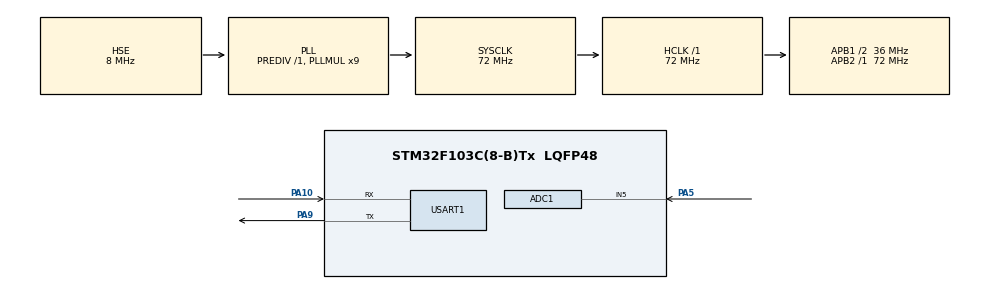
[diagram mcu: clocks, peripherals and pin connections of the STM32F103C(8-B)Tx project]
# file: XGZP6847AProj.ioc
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ADC1.Channel-0\#ChannelRegularConversion=ADC_CHANNEL_5
ADC1.ContinuousConvMode=ENABLE
ADC1.NbrOfConversionFlag=1
ADC1.Rank-0\#ChannelRegularConversion=1
ADC1.SamplingTime-0\#ChannelRegularConversion=ADC_SAMPLETIME_1CYCLE_5
ADC1.master=1
Mcu.Family=STM32F1
Mcu.Name=STM32F103C(8-B)Tx
Mcu.Package=LQFP48
NVIC.PriorityGroup=NVIC_PRIORITYGROUP_4
NVIC.USART1_IRQn=true\:0\:0\:false\:false\:true\:true\:true\:true
PA10.Mode=Asynchronous
PA10.Signal=USART1_RX
PA13.Mode=Serial_Wire
PA13.Signal=SYS_JTMS-SWDIO
PA14.Mode=Serial_Wire
PA14.Signal=SYS_JTCK-SWCLK
PA5.Signal=ADCx_IN5
PA9.Mode=Asynchronous
PA9.Signal=USART1_TX
PD0-OSC_IN.Mode=HSE-External-Oscillator
PD0-OSC_IN.Signal=RCC_OSC_IN
PD1-OSC_OUT.Mode=HSE-External-Oscillator
PD1-OSC_OUT.Signal=RCC_OSC_OUT
ProjectManager.HeapSize=0x200
ProjectManager.StackSize=0x400
ProjectManager.TargetToolchain=MDK-ARM V5.32
RCC.ADCPresc=RCC_ADCPCLK2_DIV6
RCC.AHBFreq_Value=72000000
RCC.APB1CLKDivider=RCC_HCLK_DIV2
RCC.APB1Freq_Value=36000000
RCC.APB1TimFreq_Value=72000000
RCC.APB2Freq_Value=72000000
RCC.APB2TimFreq_Value=72000000
RCC.HCLKFreq_Value=72000000
RCC.PLLMUL=RCC_PLL_MUL9
RCC.PLLSourceVirtual=RCC_PLLSOURCE_HSE
RCC.SYSCLKFreq_VALUE=72000000
RCC.SYSCLKSource=RCC_SYSCLKSOURCE_PLLCLK
RCC.USBFreq_Value=72000000
SH.ADCx_IN5.0=ADC1_IN5,IN5
USART1.VirtualMode=VM_ASYNC
board=custom

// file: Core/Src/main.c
/* USER CODE BEGIN Header */
/**
 ******************************************************************************
 * @file           : main.c
 * @brief          : Main program body
 ******************************************************************************
 * @attention
 *
 * Copyright (c) 2024 STMicroelectronics.
 * All rights reserved.
 *
 * This software is licensed under terms that can be found in the LICENSE file
 * in the root directory of this software component.
 * If no LICENSE file comes with this software, it is provided AS-IS.
 *
 ******************************************************************************
 */
/* USER CODE END Header */
#include "main.h"
#include "adc.h"
#include "gpio.h"
#include "usart.h"

/* USER CODE BEGIN Includes */
#include "Serial.h"
/* USER CODE END Includes */

/* USER CODE BEGIN PD */
#define RX_BUFFER_SIZE 5 // 定义接收缓冲区大小
/* USER CODE END PD */

/* USER CODE BEGIN PV */
int16_t ADC_Value;
float Pressure_V;
float pressure;

uint8_t RxBuffer[RX_BUFFER_SIZE]; // 接收缓冲区

int16_t RxNUM = 0;
/* USER CODE END PV */

void SystemClock_Config(void);

/* USER CODE BEGIN 0 */
HAL_StatusTypeDef HalState;
uint16_t Ret;
uint16_t Start_GetResult(void)
{
    Ret = HAL_ADC_GetValue(&hadc1);
    return Ret;
}

float map(float x, float in_min, float in_max, float out_min, float out_max)
{
    return (x - in_min) * (out_max - out_min) / (in_max - in_min) + out_min;
}

// usart1中断函数
void HAL_UART_RxCpltCallback(UART_HandleTypeDef* huart)
{
    if (huart == &huart1) {
        if (ByteRecv == 'a') {
            Serial_printf("ADC_Value:%f\n", ADC_Value);
            HAL_UART_Receive_IT(&huart1, &ByteRecv, 1);
        } else if (ByteRecv == 's') {
            Serial_printf("ADC_Value:%f\n", ADC_Value);
            HAL_UART_Receive_IT(&huart1, &ByteRecv, 1);
        }
    }
}

/* USER CODE END 0 */

int main(void)
{

    /* MCU Configuration--------------------------------------------------------*/

    /* Reset of all peripherals, Initializes the Flash interface and the Systick. */
    HAL_Init();

    /* Configure the system clock */
    SystemClock_Config();

    /* Initialize all configured peripherals */
    MX_GPIO_Init();
    MX_ADC1_Init();
    MX_USART1_UART_Init();
    /* USER CODE BEGIN 2 */

    HAL_ADCEx_Calibration_Start(&hadc1); // ADC校准

    HAL_ADC_Start(&hadc1); // 启动ADC转换  (!!!!continuous conversion mode)

    HAL_UART_Receive_IT(&huart1, &ByteRecv, 1); // start itrpt receive a byte
    /* USER CODE END 2 */

    /* Infinite loop */
    /* USER CODE BEGIN WHILE */
    while (1) {
        ADC_Value = Start_GetResult();
        Pressure_V = (float)(ADC_Value * 3.3) / 4096.0; //(ADC_Value/4096.0) * 3.3

        // 0-40kPa 0-3.3V   (pa)
        pressure = map(Pressure_V, 0.0, 3.3, 0.0, 40000.0);
        Serial_printf("pressure,Pressure_V,ADC_Value:%f,%f,%d\n", pressure, Pressure_V, ADC_Value);

        HAL_Delay(100);
        /* USER CODE END WHILE */

    }
}

void SystemClock_Config(void)
{
    RCC_OscInitTypeDef RCC_OscInitStruct = { 0 };
    RCC_ClkInitTypeDef RCC_ClkInitStruct = { 0 };
    RCC_PeriphCLKInitTypeDef PeriphClkInit = { 0 };

    /** Initializes the RCC Oscillators according to the specified parameters
     * in the RCC_OscInitTypeDef structure.
     */
    RCC_OscInitStruct.OscillatorType = RCC_OSCILLATORTYPE_HSE;
    RCC_OscInitStruct.HSEState = RCC_HSE_ON;
    RCC_OscInitStruct.HSEPredivValue = RCC_HSE_PREDIV_DIV1;
    RCC_OscInitStruct.HSIState = RCC_HSI_ON;
    RCC_OscInitStruct.PLL.PLLState = RCC_PLL_ON;
    RCC_OscInitStruct.PLL.PLLSource = RCC_PLLSOURCE_HSE;
    RCC_OscInitStruct.PLL.PLLMUL = RCC_PLL_MUL9;
    if (HAL_RCC_OscConfig(&RCC_OscInitStruct) != HAL_OK) {
        Error_Handler();
    }

    /** Initializes the CPU, AHB and APB buses clocks
     */
    RCC_ClkInitStruct.ClockType = RCC_CLOCKTYPE_HCLK | RCC_CLOCKTYPE_SYSCLK
        | RCC_CLOCKTYPE_PCLK1 | RCC_CLOCKTYPE_PCLK2;
    RCC_ClkInitStruct.SYSCLKSource = RCC_SYSCLKSOURCE_PLLCLK;
    RCC_ClkInitStruct.AHBCLKDivider = RCC_SYSCLK_DIV1;
    RCC_ClkInitStruct.APB1CLKDivider = RCC_HCLK_DIV2;
    RCC_ClkInitStruct.APB2CLKDivider = RCC_HCLK_DIV1;

    if (HAL_RCC_ClockConfig(&RCC_ClkInitStruct, FLASH_LATENCY_2) != HAL_OK) {
        Error_Handler();
    }
    PeriphClkInit.PeriphClockSelection = RCC_PERIPHCLK_ADC;
    PeriphClkInit.AdcClockSelection = RCC_ADCPCLK2_DIV6;
    if (HAL_RCCEx_PeriphCLKConfig(&PeriphClkInit) != HAL_OK) {
        Error_Handler();
    }
}

void Error_Handler(void)
{
    __disable_irq();
    while (1) {
    }
}
